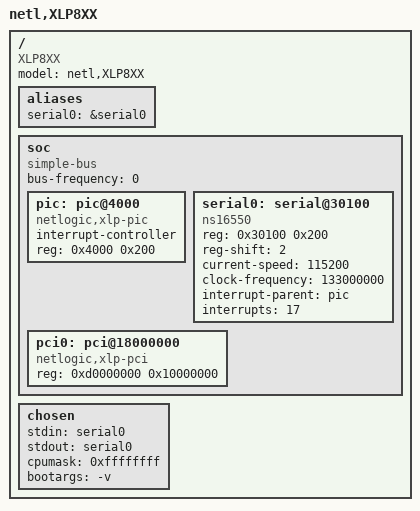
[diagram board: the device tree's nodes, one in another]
/*
 * Copyright (c) 2010 The FreeBSD Foundation
 * All rights reserved.
 *
 * Redistribution and use in source and binary forms, with or without
 * modification, are permitted provided that the following conditions
 * are met:
 * 1. Redistributions of source code must retain the above copyright
 *    notice, this list of conditions and the following disclaimer.
 * 2. Redistributions in binary form must reproduce the above copyright
 *    notice, this list of conditions and the following disclaimer in the
 *    documentation and/or other materials provided with the distribution.
 *
 * THIS SOFTWARE IS PROVIDED BY THE AUTHOR AND CONTRIBUTORS ``AS IS'' AND
 * ANY EXPRESS OR IMPLIED WARRANTIES, INCLUDING, BUT NOT LIMITED TO, THE
 * IMPLIED WARRANTIES OF MERCHANTABILITY AND FITNESS FOR A PARTICULAR PURPOSE
 * ARE DISCLAIMED. IN NO EVENT SHALL THE AUTHOR OR CONTRIBUTORS BE LIABLE
 * FOR ANY DIRECT, INDIRECT, INCIDENTAL, SPECIAL, EXEMPLARY, OR CONSEQUENTIAL
 * DAMAGES (INCLUDING, BUT NOT LIMITED TO, PROCUREMENT OF SUBSTITUTE GOODS
 * OR SERVICES; LOSS OF USE, DATA, OR PROFITS; OR BUSINESS INTERRUPTION)
 * HOWEVER CAUSED AND ON ANY THEORY OF LIABILITY, WHETHER IN CONTRACT, STRICT
 * LIABILITY, OR TORT (INCLUDING NEGLIGENCE OR OTHERWISE) ARISING IN ANY WAY
 * OUT OF THE USE OF THIS SOFTWARE, EVEN IF ADVISED OF THE POSSIBILITY OF
 * SUCH DAMAGE.
 *
 * Netlogic Microsystems XLP8xx Device Tree Source.
 *
 * $FreeBSD$
 */

/dts-v1/;

/ {
	model = "netl,XLP8XX";
	compatible = "XLP8XX";
	#address-cells = <1>;
	#size-cells = <1>;

	aliases {
		serial0 = &serial0;
	};

	soc {
		#address-cells = <1>;
		#size-cells = <1>;
		compatible = "simple-bus";
		ranges = <0x0 0x18000000 0x04000000>;
		bus-frequency = <0>;

		pic: pic@4000 {
			compatible = "netlogic,xlp-pic";
			interrupt-controller;
			#address-cells = <0>;
			#interrupt-cells = <1>;
			reg = <0x4000 0x200>;
		};

		serial0: serial@30100 {
			compatible = "ns16550";
			reg = <0x30100 0x200>;
			reg-shift = <2>;
			current-speed = <115200>;
			clock-frequency = <133000000>;
			interrupt-parent = <&pic>;
			interrupts = <17>;
		};

		pci0: pci@18000000 {
			compatible = "netlogic,xlp-pci", "pci";
			reg = <0xd0000000 0x10000000>;
		};
	};

	chosen {
		stdin = "serial0";
		stdout = "serial0";
		cpumask = <0xffffffff>;
		bootargs = "-v"; 
	};
};
